AUTOSAR XML (schema 4-2-2)
package /ComponentTypes
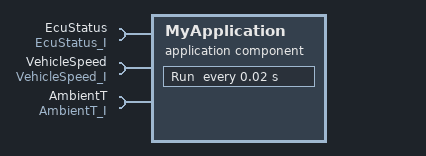
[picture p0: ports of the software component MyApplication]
  application sw component type MyApplication
    require port EcuStatus: required-interface=EcuStatus_I
      required-com-specs:
        data-element=EcuU, filter=data-filter-type=ALWAYS, init-value=constant-reference=EcuU_IV
        data-element=RebootCount, filter=data-filter-type=ALWAYS, init-value=constant-reference=RebootCount_IV
    require port VehicleSpeed: nonqueued-receiver-com-spec{data-element=VehicleSpeed, filter=data-filter-type=ALWAYS, init-value=constant-reference=VehicleSpeed_IV}, required-interface=VehicleSpeed_I
    require port AmbientT: nonqueued-receiver-com-spec{data-element=AmbientT, filter=data-filter-type=ALWAYS, init-value=constant-reference=AmbientT_IV}, required-interface=AmbientT_I
    behavior MyApplication_InternalBehavior
      timing event TMT_Run: start-on-event=Run, period=0.02
      4 x data received event:
        DRT_AmbientT_Received_AmbientT_AmbientT: start-on-event=AmbientT_Received, data=AmbientT.AmbientT
        DRT_VehicleSpeed_Received_VehicleSpeed_VehicleSpeed: start-on-event=VehicleSpeed_Received, data=VehicleSpeed.VehicleSpeed
        DRT_EcuU_Received_EcuStatus_EcuU: start-on-event=EcuU_Received, data=EcuStatus.EcuU
        DRT_RebootCount_Received_EcuStatus_RebootCount: start-on-event=RebootCount_Received, data=EcuStatus.RebootCount
      port-api-options:
        enable-take-address=false, indirect-api=false, port=AmbientT
        enable-take-address=false, indirect-api=false, port=EcuStatus
        enable-take-address=false, indirect-api=false, port=VehicleSpeed
      5 x runnable:
        Run
          data-receive-point-by-arguments:
            4 x access:
              REC_VehicleSpeed_VehicleSpeed: accessed-variable=VehicleSpeed.VehicleSpeed
              REC_AmbientT_AmbientT: accessed-variable=AmbientT.AmbientT
              REC_EcuStatus_EcuU: accessed-variable=EcuStatus.EcuU
              REC_EcuStatus_RebootCount: accessed-variable=EcuStatus.RebootCount
        AmbientT_Received
          data-receive-point-by-arguments:
            access REC_AmbientT_AmbientT: accessed-variable=AmbientT.AmbientT
        VehicleSpeed_Received
          data-receive-point-by-arguments:
            access REC_VehicleSpeed_VehicleSpeed: accessed-variable=VehicleSpeed.VehicleSpeed
        EcuU_Received
          data-receive-point-by-arguments:
            access REC_EcuStatus_EcuU: accessed-variable=EcuStatus.EcuU
        RebootCount_Received: minimum-start-interval=0.005
          data-receive-point-by-arguments:
            access REC_EcuStatus_RebootCount: accessed-variable=EcuStatus.RebootCount
  swc implementation MyApplication_Implementation: behavior=MyApplication_InternalBehavior
    code-descriptors:
      code Default: artifact-descriptors=autosar-engineering-object={short-label=Default, category=SWSRC}
